NS_ :

BS_:

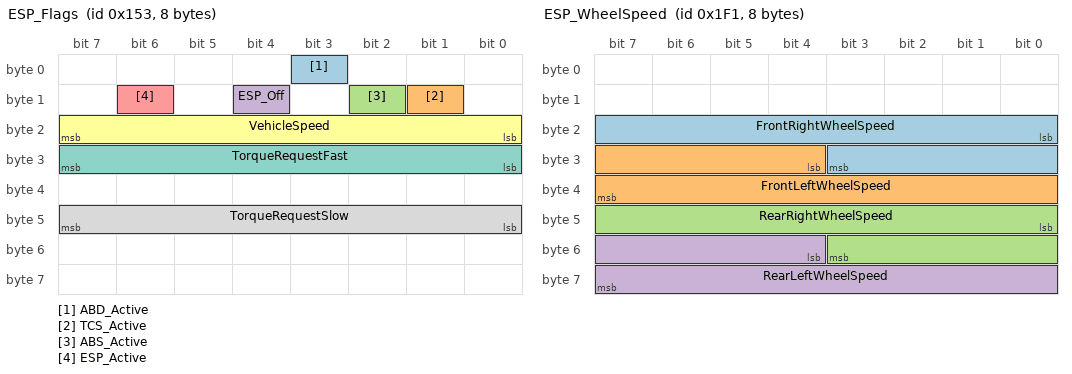
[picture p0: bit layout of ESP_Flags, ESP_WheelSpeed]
BO_ 339 ESP_Flags: 8 ESP
 SG_ ABD_Active : 3|1@1+ (1,0) [0|1] "yes/no"  AWD,ECU,TCU
 SG_ TCS_Active : 9|1@1+ (1,0) [0|1] "yes/no"  AWD,ECU,TCU
 SG_ ABS_Active : 10|1@1+ (1,0) [0|1] "yes/no"  AWD,ECU,TCU
 SG_ ESP_Off : 12|1@1+ (1,0) [0|1] "yes/no"  AWD,ECU,TCU
 SG_ ESP_Active : 14|1@1+ (1,0) [0|1] "yes/no"  AWD,ECU,TCU
 SG_ VehicleSpeed : 16|8@1+ (1,0) [0|254] "km/h"  AWD,ECU,TCU
 SG_ TorqueRequestFast : 24|8@1+ (0.390625,0) [0|99.609375] "%"  ECU,TCU
 SG_ TorqueRequestSlow : 40|8@1+ (0.390625,0) [0|99.609375] "%"  ECU,TCU

BO_ 497 ESP_WheelSpeed: 8 ESP
 SG_ FrontRightWheelSpeed : 16|12@1+ (0.125,0) [0|511.875] "km/h"  AWD
 SG_ FrontLeftWheelSpeed : 28|12@1+ (0.125,0) [0|511.875] "km/h"  AWD
 SG_ RearRightWheelSpeed : 40|12@1+ (0.125,0) [0|511.875] "km/h"  AWD
 SG_ RearLeftWheelSpeed : 52|12@1+ (0.125,0) [0|511.875] "km/h"  AWD

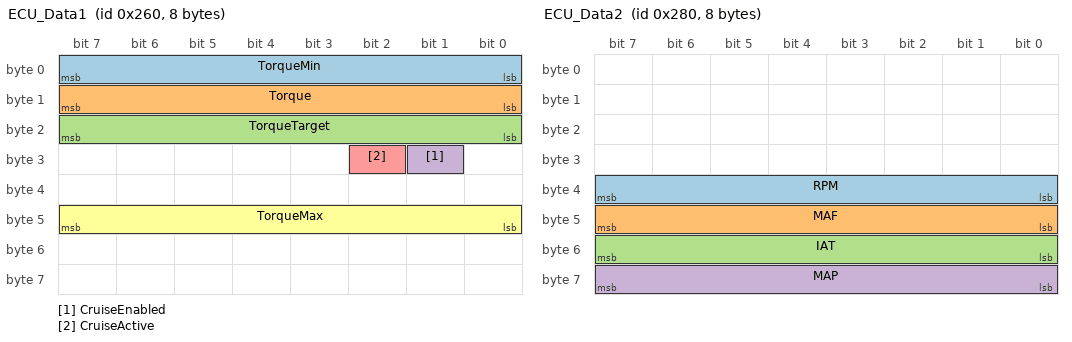
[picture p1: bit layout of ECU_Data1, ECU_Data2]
BO_ 608 ECU_Data1: 8 ECU
 SG_ TorqueMin : 0|8@1+ (0.390625,0) [0|99.609375] "%"  ESP,TCU
 SG_ Torque : 8|8@1+ (0.390625,0) [0|99.609375] "%"  ESP,TCU
 SG_ TorqueTarget : 16|8@1+ (0.390625,0) [0|99.609375] "%"  ESP,TCU
 SG_ CruiseEnabled : 25|1@1+ (1,0) [0|1] "yes/no"  TCU
 SG_ CruiseActive : 26|1@1+ (1,0) [0|1] "yes/no"  TCU
 SG_ TorqueMax : 40|8@1+ (0.390625,0) [0|99.609375] "%"  ESP,TCU

BO_ 640 ECU_Data2: 8 ECU
 SG_ RPM : 32|8@1+ (32,0) [0|8160] "rpm"  TCU
 SG_ MAF : 40|8@1+ (5.447,0) [0|1388.985] "mg/TDC"  TCU
 SG_ IAT : 48|8@1- (0.75,-48) [-48|143.25] "C"  TCU
 SG_ MAP : 56|8@1+ (0.47058,0) [0|119.9979] "KPa"  TCU

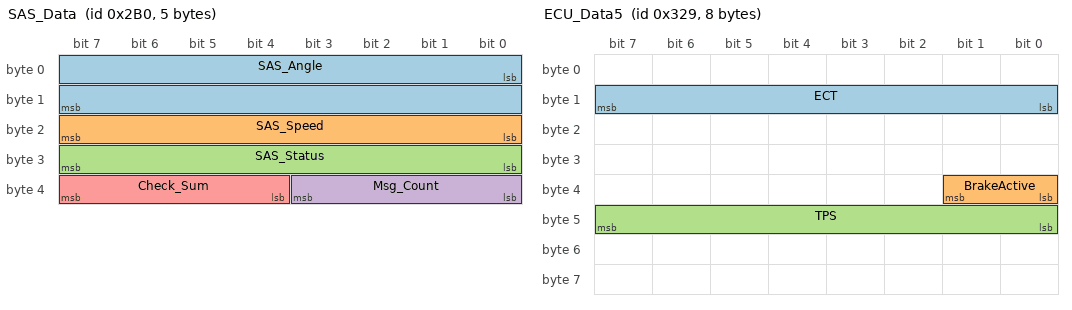
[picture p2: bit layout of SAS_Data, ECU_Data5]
BO_ 688 SAS_Data: 5 SAS
 SG_ SAS_Angle : 0|16@1- (0.1,0) [-3276.8|3276.7] "deg"  AWD,ECU,ESP,TCU
 SG_ SAS_Speed : 16|8@1+ (4,0) [0|1016] "deg/s"  ESP,TCU
 SG_ SAS_Status : 24|8@1+ (1,0) [0|255] ""  ESP,TCU
 SG_ Msg_Count : 32|4@1+ (1,0) [0|15] ""  ESP
 SG_ Check_Sum : 36|4@1+ (1,0) [0|15] ""  ECU,ESP

BO_ 809 ECU_Data5: 8 ECU
 SG_ ECT : 8|8@1- (0.75,-48) [-48|143.25] "C"  AWD,ABS,ESP,TCU
 SG_ BrakeActive : 32|2@1+ (1,0) [0|3] "yes/no"  AWD,ABS,ESP,TCU
 SG_ TPS : 40|8@1+ (0.47265625,-15) [-15|105.52734375] "%"  AWD,ABS,ESP,TCU

BO_ 1064 AWD_Data1: 8 AWD
 SG_ ClutchDuty : 16|8@1+ (1,0) [0|100] "%"  ABS,ESP
 SG_ ClutchLocked : 44|1@1+ (1,0) [0|1] "yes/no"  ABS,ESP

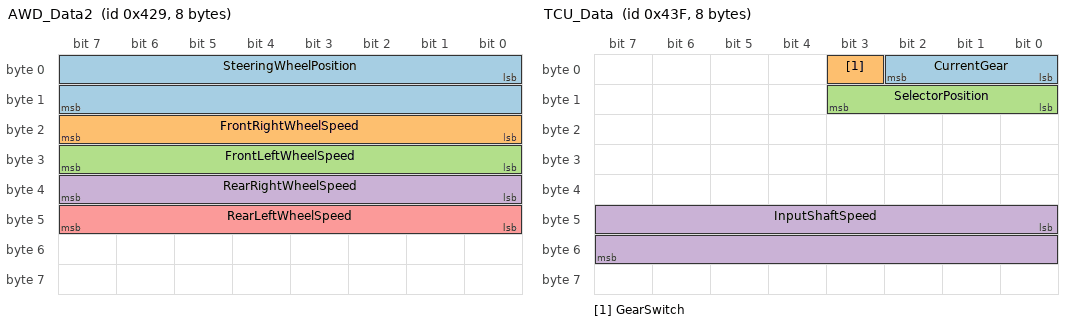
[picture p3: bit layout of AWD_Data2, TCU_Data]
BO_ 1065 AWD_Data2: 8 AWD
 SG_ SteeringWheelPosition : 0|16@1+ (1,-600) [-600|600] "deg"  ABS
 SG_ FrontRightWheelSpeed : 16|8@1+ (1,0) [0|254] "km/h"  ABS
 SG_ FrontLeftWheelSpeed : 24|8@1+ (1,0) [0|254] "km/h"  ABS
 SG_ RearRightWheelSpeed : 32|8@1+ (1,0) [0|254] "km/h"  ABS
 SG_ RearLeftWheelSpeed : 40|8@1+ (1,0) [0|254] "km/h"  ABS

BO_ 1087 TCU_Data: 8 TCU
 SG_ CurrentGear : 0|3@1+ (1,0) [0|7] ""  ECU
 SG_ GearSwitch : 3|1@1+ (1,0) [0|1] "yes/no"  ECU
 SG_ SelectorPosition : 8|4@1+ (1,0) [0|15] ""  ECU
 SG_ InputShaftSpeed : 40|16@1+ (0.25,0) [0|16383.5] "rpm"  ECU

BO_ 1349 ECU_Data6: 8 ECU
 SG_ BatteryVoltage : 24|8@1+ (0.1015625,0) [0|25.8984375] "V"  ABS,ESP

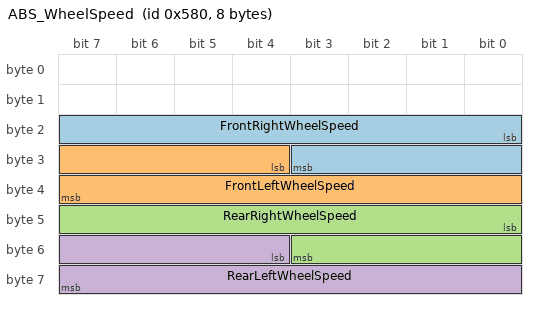
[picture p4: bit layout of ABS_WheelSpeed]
BO_ 1408 ABS_WheelSpeed: 8 ABS
 SG_ FrontRightWheelSpeed : 16|12@1+ (0.125,0) [0|511.875] "km/h"  AWD
 SG_ FrontLeftWheelSpeed : 28|12@1+ (0.125,0) [0|511.875] "km/h"  AWD
 SG_ RearRightWheelSpeed : 40|12@1+ (0.125,0) [0|511.875] "km/h"  AWD
 SG_ RearLeftWheelSpeed : 52|12@1+ (0.125,0) [0|511.875] "km/h"  AWD

BO_ 1695 ECU_Data7: 8 ECU
 SG_ ECU_Temperature : 8|8@1- (1,-28) [-28|227] "C"  TCU

BO_ 1984 SAS_Calibration: 2 ESP
 SG_ CCW : 0|4@1+ (1,0) [0|15] ""  SAS
 SG_ CID : 4|11@1+ (1,0) [0|2047] ""  SAS

BU_: GMLAN NEO
VAL_TABLE_ GearShifter 3 "Park" 0 "Drive/Low" ;
VAL_TABLE_ DriverDoorStatus 1 "Opened" 0 "Closed" ;
VAL_TABLE_ LKAGapButton 2 "???" 1 "??" 0 "None" ;
VAL_TABLE_ CruiseButtons 6 "Cancel" 5 "Main" 3 "Set" 2 "Resume" 1 "None" ;
VAL_TABLE_ CruiseControlActive 1 "Active" 0 "Inactive" ;
VAL_TABLE_ BlinkerStatus 1 "Active" 0 "Inactive" ;

CM_ SG_ 36 ACCEL_Y "unit is tbd";
CM_ SG_ 36 STEERING_TORQUE "does not seem the steer torque, tbd";
CM_ SG_ 36 YAW_RATE "verify";
CM_ SG_ 466 ACCEL_NET "net acceleration produced by the system, given ACCEL_CMD, road grade and other factors";
CM_ SG_ 466 CRUISE_STATE "Active state is 8, if standstill is requested will switch to state 11(3 sec timer), after timer is elapsed will switch into state 7(standstill). If plus button was pressed - status 9, minus button pressed - status 10";
CM_ SG_ 550 BRAKE_PRESSURE "seems prop to pedal force";
CM_ SG_ 550 BRAKE_POSITION "seems proportional to pedal displacement, unclear the max value of 0x1c8";
CM_ SG_ 560 BRAKE_LIGHTS "double check";
CM_ SG_ 581 GAS_PEDAL "it seems slightly filtered";
CM_ SG_ 608 STEER_TORQUE_DRIVER "driver torque";
CM_ SG_ 608 STEER_OVERRIDE "set when driver torque exceeds a certain value";
CM_ SG_ 614 ANGLE "set to measured angle when ipas control isn't active";
CM_ SG_ 37 STEER_FRACTION "1/15th of the signal STEER_ANGLE, which is 1.5 deg; note that 0x8 is never set";
CM_ SG_ 37 STEER_RATE "factor is tbd";
CM_ SG_ 467 LOW_SPEED_LOCKOUT "in low speed lockout, system would always disengage below 28mph";
CM_ SG_ 467 SET_SPEED "43 kph are shown as 28mph, so conversion isn't perfect";
CM_ SG_ 921 UI_SET_SPEED "set speed shown in UI with user set unit";
CM_ SG_ 1042 SET_ME_1 "unclear what this is, nut it's always 1 in drive traces";
